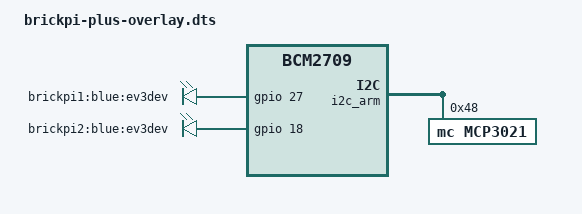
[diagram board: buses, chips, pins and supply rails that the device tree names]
// Definitions for Dexter Industries BrickPi+
// http://www.dexterindustries.com/BrickPi/
/dts-v1/;
/plugin/;

/ {
	compatible = "brcm,bcm2708", "brcm,bcm2709";

	fragment@0 {
		target = <&i2c_arm>;
		__overlay__ {
			#address-cells = <1>;
			#size-cells = <0>;
			status = "okay";

			// TODO: Would be better as a power_supply driver
			// See https://github.com/ev3dev/ev3dev/issues/413
			mcp3021: mcp3021@48 {
				compatible = "mc,mcp3021";
				reg = <0x48>;
				status = "okay";
			};
		};
	};

	fragment@1 {
		target = <&leds>;
		__overlay__ {
			brickpi_led1: bpi1 {
				label = "brickpi1:blue:ev3dev";
				linux,default-trigger = "default-on";
				// override is needed for rev 1 board where this is gpio 21 instead
				gpios = <&gpio 27 0>;
			};
			brickpi_led2: bpi2 {
				label = "brickpi2:blue:ev3dev";
				linux,default-trigger = "default-on";
				gpios = <&gpio 18 0>;
			};
		};
	};

	// TODO: Should add an option to enable the gpio for the RESET line

	__overrides__ {
		brickpi_led1_gpio = <&brickpi_led1>,"gpios:4";
		brickpi_led1_trigger = <&brickpi_led1>,"linux,default-trigger";
		brickpi_led2_gpio = <&brickpi_led2>,"gpios:4";
		brickpi_led2_trigger = <&brickpi_led2>,"linux,default-trigger";
	};
};
